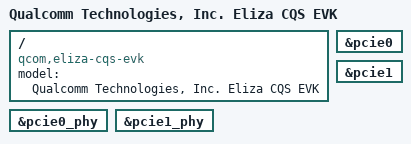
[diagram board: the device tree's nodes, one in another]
// SPDX-License-Identifier: BSD-3-Clause
/*
 * Copyright (c) Qualcomm Technologies, Inc. and/or its subsidiaries.
 */

/dts-v1/;

#include "eliza-cqs-som.dtsi"
#include "eliza-evk.dtsi"

/ {
	model = "Qualcomm Technologies, Inc. Eliza CQS EVK";
	compatible = "qcom,eliza-cqs-evk", "qcom,eliza-cqs-som", "qcom,eliza";
};

&pcie0 {
	status = "okay";
};

&pcie0_phy {
	status = "okay";
};

&pcie1 {
	status = "okay";
};

&pcie1_phy {
	status = "okay";
};
